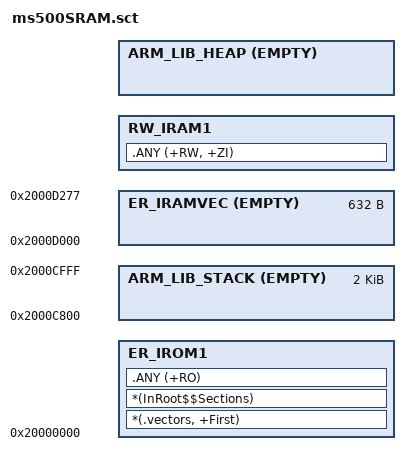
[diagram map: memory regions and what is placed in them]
#! armcc -E
#if !defined(APP_START)
    #define APP_START      0x20000000
#endif

#if !defined(APP_SIZE)
    #define APP_SIZE 0x0000C800
#endif

#if !defined(STACK_START)
    #define STACK_START 0x2000C800
#endif

#if !defined(STACK_SIZE)
    #define STACK_SIZE  0x00000800
#endif

#if !defined(HEAP_START)
    #define HEAP_START 0x20010000
#endif

#if !defined(HEAP_SIZE)
    #define HEAP_SIZE  0x00000800
#endif

LR_IROM1 APP_START {
    ER_IROM1 APP_START { ; load address = execurino address
        *(.vectors, +First)
        *(InRoot$$Sections)
        .ANY (+RO)
    }
    ARM_LIB_STACK STACK_START EMPTY STACK_SIZE {
    }

    ER_IRAMVEC STACK_START+STACK_SIZE EMPTY (4*(16 + 142)) {  ; Reserve for vectors
    }

    RW_IRAM1 AlignExpr(+0,16) {  ; 16 byte-aligned    
        .ANY (+RW, +ZI)
    }

   ; Extern SRAM for HEAP
   ARM_LIB_HEAP AlignExpr(+0, 16) EMPTY (HEAP_START - AlignExpr(ImageLimit(RW_IRAM1), 16)) {
   }

}
ScatterAssert(LoadLimit(LR_IROM1) <= (APP_START + APP_SIZE))    ; 64 KB SRAM (internal)
ScatterAssert(ImageLimit(RW_IRAM1) <= HEAP_START)   ; 64 KB SRAM (internal)
